AUTOSAR XML (schema 4-3-0)
package /Impl_SWC_HALOUT_ARPkg
  swc implementation Impl_SWC_HALOUT_type: programming-language=C, sw-version=1.0.0, vendor-id=0, behavior=SWC_HALOUT_type_IB
    code-descriptors:
      code SRC: artifact-descriptors=autosar-engineering-object={short-label=EngObject, category=SWSRC}
    resource consumption ResourceConsumption
      memory section MEM_SWC_HALOUT_CAL: size=0, sw-addrmethod=CAL, symbol=CAL
      memory section MEM_SWC_HALOUT_CODE: size=0, sw-addrmethod=CODE, symbol=CODE
package /SWC_HALOUT_ARPkg
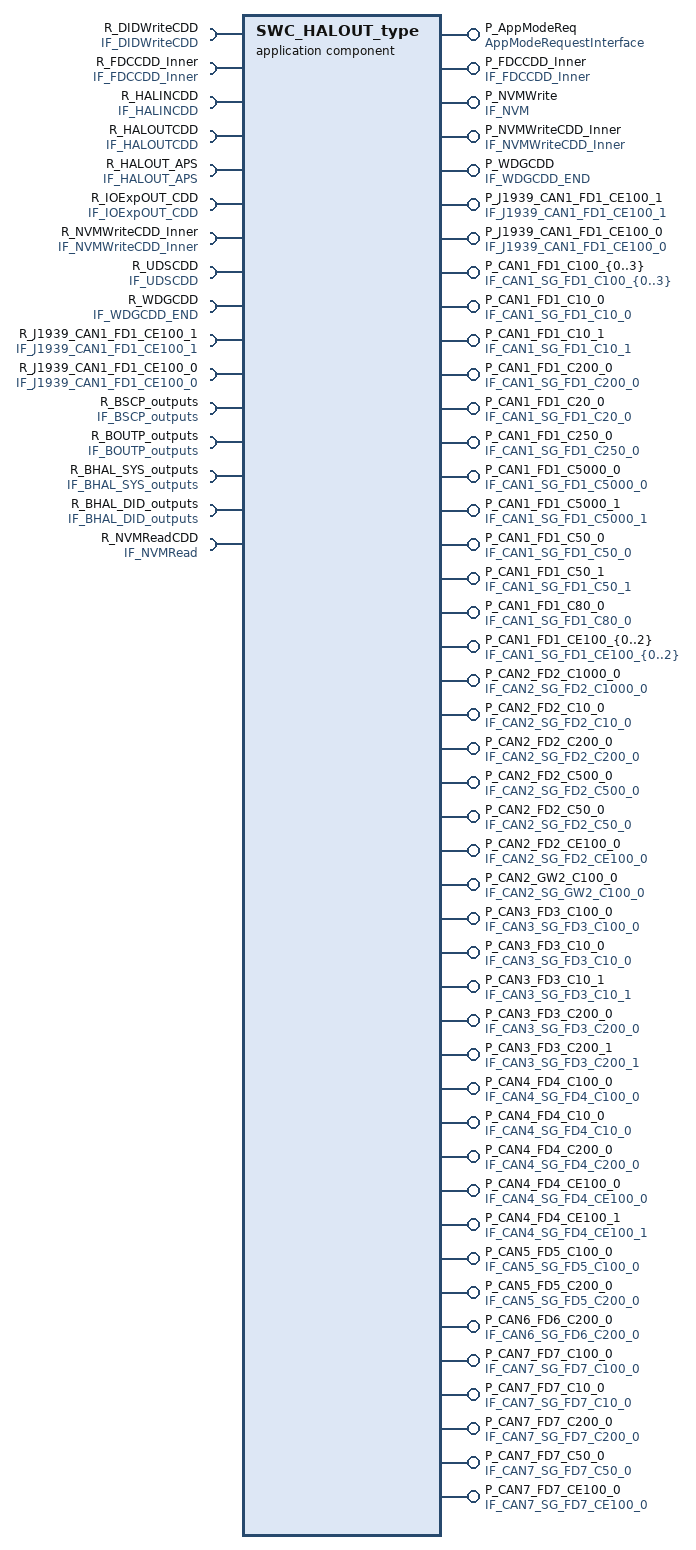
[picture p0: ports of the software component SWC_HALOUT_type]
  application sw component type SWC_HALOUT_type
    49 x provide port:
      P_AppModeReq: provided-interface=AppModeRequestInterface
      P_FDCCDD_Inner: provided-interface=IF_FDCCDD_Inner
      P_NVMWrite: nv-provide-com-spec{ram-block-init-value=ValueSpecification_:1024 x 0, rom-block-init-value=ValueSpecification_:1024 x 0, variable=NV_FVTDataArray}, provided-interface=IF_NVM
      P_NVMWriteCDD_Inner: provided-interface=IF_NVMWriteCDD_Inner
      P_WDGCDD: provided-interface=IF_WDGCDD_END
      P_J1939_CAN1_FD1_CE100_1: provided-interface=IF_J1939_CAN1_FD1_CE100_1
      P_J1939_CAN1_FD1_CE100_0: provided-interface=IF_J1939_CAN1_FD1_CE100_0
      P_CAN1_FD1_C100_{0..3}: provided-interface=IF_CAN1_SG_FD1_C100_{0..3}
      P_CAN1_FD1_C10_0: provided-interface=IF_CAN1_SG_FD1_C10_0
      P_CAN1_FD1_C10_1: provided-interface=IF_CAN1_SG_FD1_C10_1
      P_CAN1_FD1_C200_0: provided-interface=IF_CAN1_SG_FD1_C200_0
      P_CAN1_FD1_C20_0: provided-interface=IF_CAN1_SG_FD1_C20_0
      P_CAN1_FD1_C250_0: provided-interface=IF_CAN1_SG_FD1_C250_0
      P_CAN1_FD1_C5000_0: provided-interface=IF_CAN1_SG_FD1_C5000_0
      P_CAN1_FD1_C5000_1: provided-interface=IF_CAN1_SG_FD1_C5000_1
      P_CAN1_FD1_C50_0: provided-interface=IF_CAN1_SG_FD1_C50_0
      P_CAN1_FD1_C50_1: provided-interface=IF_CAN1_SG_FD1_C50_1
      P_CAN1_FD1_C80_0: provided-interface=IF_CAN1_SG_FD1_C80_0
      P_CAN1_FD1_CE100_{0..2}: provided-interface=IF_CAN1_SG_FD1_CE100_{0..2}
      P_CAN2_FD2_C1000_0: provided-interface=IF_CAN2_SG_FD2_C1000_0
      P_CAN2_FD2_C10_0: provided-interface=IF_CAN2_SG_FD2_C10_0
      P_CAN2_FD2_C200_0: provided-interface=IF_CAN2_SG_FD2_C200_0
      P_CAN2_FD2_C500_0: provided-interface=IF_CAN2_SG_FD2_C500_0
      P_CAN2_FD2_C50_0: provided-interface=IF_CAN2_SG_FD2_C50_0
      P_CAN2_FD2_CE100_0: provided-interface=IF_CAN2_SG_FD2_CE100_0
      P_CAN2_GW2_C100_0: provided-interface=IF_CAN2_SG_GW2_C100_0
      P_CAN3_FD3_C100_0: provided-interface=IF_CAN3_SG_FD3_C100_0
      P_CAN3_FD3_C10_0: provided-interface=IF_CAN3_SG_FD3_C10_0
      P_CAN3_FD3_C10_1: provided-interface=IF_CAN3_SG_FD3_C10_1
      P_CAN3_FD3_C200_0: provided-interface=IF_CAN3_SG_FD3_C200_0
      P_CAN3_FD3_C200_1: provided-interface=IF_CAN3_SG_FD3_C200_1
      P_CAN4_FD4_C100_0: provided-interface=IF_CAN4_SG_FD4_C100_0
      P_CAN4_FD4_C10_0: provided-interface=IF_CAN4_SG_FD4_C10_0
      P_CAN4_FD4_C200_0: provided-interface=IF_CAN4_SG_FD4_C200_0
      P_CAN4_FD4_CE100_0: provided-interface=IF_CAN4_SG_FD4_CE100_0
      P_CAN4_FD4_CE100_1: provided-interface=IF_CAN4_SG_FD4_CE100_1
      P_CAN5_FD5_C100_0: provided-interface=IF_CAN5_SG_FD5_C100_0
      P_CAN5_FD5_C200_0: provided-interface=IF_CAN5_SG_FD5_C200_0
      P_CAN6_FD6_C200_0: provided-interface=IF_CAN6_SG_FD6_C200_0
      P_CAN7_FD7_C100_0: provided-interface=IF_CAN7_SG_FD7_C100_0
      P_CAN7_FD7_C10_0: provided-interface=IF_CAN7_SG_FD7_C10_0
      P_CAN7_FD7_C200_0: provided-interface=IF_CAN7_SG_FD7_C200_0
      P_CAN7_FD7_C50_0: provided-interface=IF_CAN7_SG_FD7_C50_0
      P_CAN7_FD7_CE100_0: provided-interface=IF_CAN7_SG_FD7_CE100_0
    16 x require port:
      R_DIDWriteCDD: required-interface=IF_DIDWriteCDD
      R_FDCCDD_Inner: required-interface=IF_FDCCDD_Inner
      R_HALINCDD: required-interface=IF_HALINCDD
      R_HALOUTCDD: required-interface=IF_HALOUTCDD
      R_HALOUT_APS: required-interface=IF_HALOUT_APS
      R_IOExpOUT_CDD: required-interface=IF_IOExpOUT_CDD
      R_NVMWriteCDD_Inner: required-interface=IF_NVMWriteCDD_Inner
      R_UDSCDD: required-interface=IF_UDSCDD
      R_WDGCDD: required-interface=IF_WDGCDD_END
      R_J1939_CAN1_FD1_CE100_1: required-interface=IF_J1939_CAN1_FD1_CE100_1
      R_J1939_CAN1_FD1_CE100_0: required-interface=IF_J1939_CAN1_FD1_CE100_0
      R_BSCP_outputs: required-interface=IF_BSCP_outputs
      R_BOUTP_outputs: required-interface=IF_BOUTP_outputs
      R_BHAL_SYS_outputs: required-interface=IF_BHAL_SYS_outputs
      R_BHAL_DID_outputs: required-interface=IF_BHAL_DID_outputs
      R_NVMReadCDD: required-interface=IF_NVMRead
    behavior SWC_HALOUT_type_IB: data-type-mapping=AppModeTypeMap, handle-termination-and-restart=NO-SUPPORT
      13 x timing event:
        TE_HALOUT_100ms: start-on-event=run_SWC_HALOUT_Tx_100ms, period=0.1
        TE_HALOUT_1000ms: start-on-event=run_SWC_HALOUT_Tx_1000ms, period=1
        TE_HALOUT_20ms: start-on-event=run_SWC_HALOUT_Tx_20ms, period=0.02
        TE_HALOUT_200ms: start-on-event=run_SWC_HALOUT_Tx_200ms, period=0.2
        TE_HALOUT_250ms: start-on-event=run_SWC_HALOUT_Tx_250ms, period=0.25
        TE_HALOUT_50ms: start-on-event=run_SWC_HALOUT_Tx_50ms, period=0.05
        TE_HALOUT_500ms: start-on-event=run_SWC_HALOUT_Tx_500ms, period=0.5
        TE_HALOUT_5000ms: start-on-event=run_SWC_HALOUT_Tx_5000ms, period=5
        TE_HALOUT_80ms: start-on-event=run_SWC_HALOUT_Tx_80ms, period=0.08
        TE_HALOUT_10ms: start-on-event=run_SWC_HALOUT_Tx_10ms, period=0.01
        TE_HALOUT_5ms: start-on-event=run_SWC_HALOUT_Tx_5ms, period=0.005
        TE_PAS_1ms: start-on-event=run_SWC_HALOUT_PAS_1ms, period=0.001
        TE_UDS_10ms: start-on-event=run_SWC_HALOUT_UDS_10ms, period=0.01
      5 x operation invoked event:
        oie_P_WDGCDD_CSOP_Call_WDG_AppEnd: start-on-event=run_SWC_HALOUT_AppCallWDG_End, operation=P_WDGCDD.CSOP_Call_WDG_AppEnd
        oie_P_FDCCDD_Inner_CSOP_FDC_AppCallSleep: start-on-event=run_SWC_HALOUT_AppCallSleep, operation=P_FDCCDD_Inner.CSOP_FDC_AppCallSleep
        oie_P_NVMWriteCDD_Inner_NVM_WriteOperation: start-on-event=run_SWC_HALOUT_NvmWrite, operation=P_NVMWriteCDD_Inner.NVM_WriteOperation
        oie_P_J1939_CAN1_FD1_CE100_1_CSOP_Write_FD1_CE100_1: start-on-event=run_SWC_HALOUT_J1939_Write_CAN1_FD1_CE100_1, operation=P_J1939_CAN1_FD1_CE100_1.CSOP_Write_CAN1_FD1_CE100_1
        oie_P_J1939_CAN1_FD1_CE100_0_CSOP_Write_FD1_CE100_0: start-on-event=run_SWC_HALOUT_J1939_Write_CAN1_FD1_CE100_0, operation=P_J1939_CAN1_FD1_CE100_0.CSOP_Write_CAN1_FD1_CE100_0
      explicit-inter-runnable-variables:
        44 x data:
          IRV_ms10_CAN1_SG_FD1_C10_0: type=DT_CAN1_SG_FD1_C10_0
          IRV_ms10_CAN1_SG_FD1_C10_1: type=DT_CAN1_SG_FD1_C10_1
          IRV_ms10_CAN2_SG_FD2_C10_0: type=DT_CAN2_SG_FD2_C10_0
          IRV_ms10_CAN3_SG_FD3_C10_0: type=DT_CAN3_SG_FD3_C10_0
          IRV_ms10_CAN3_SG_FD3_C10_1: type=DT_CAN3_SG_FD3_C10_1
          IRV_ms10_CAN4_SG_FD4_C10_0: type=DT_CAN4_SG_FD4_C10_0
          IRV_ms10_CAN7_SG_FD7_C10_0: type=DT_CAN7_SG_FD7_C10_0
          IRV_ms100_CAN1_SG_FD1_C100_{0..3}: type=DT_CAN1_SG_FD1_C100_{0..3}
          IRV_ms100_CAN2_SG_GW2_C100_0: type=DT_CAN2_SG_GW2_C100_0
          IRV_ms100_CAN{3..5}_SG_FD{3..5}_C100_0: type=DT_CAN{3..5}_SG_FD{3..5}_C100_0
          IRV_ms100_CAN7_SG_FD7_C100_0: type=DT_CAN7_SG_FD7_C100_0
          IRV_ms1000_CAN2_SG_FD2_C1000_0: type=DT_CAN2_SG_FD2_C1000_0
          IRV_ms20_CAN1_SG_FD1_C20_0: type=DT_CAN1_SG_FD1_C20_0
          IRV_ms200_CAN{1..3}_SG_FD{1..3}_C200_0: type=DT_CAN{1..3}_SG_FD{1..3}_C200_0
          IRV_ms200_CAN3_SG_FD3_C200_1: type=DT_CAN3_SG_FD3_C200_1
          IRV_ms200_CAN{4..7}_SG_FD{4..7}_C200_0: type=DT_CAN{4..7}_SG_FD{4..7}_C200_0
          IRV_ms250_CAN1_SG_FD1_C250_0: type=DT_CAN1_SG_FD1_C250_0
          IRV_ms50_CAN1_SG_FD1_C50_0: type=DT_CAN1_SG_FD1_C50_0
          IRV_ms50_CAN1_SG_FD1_C50_1: type=DT_CAN1_SG_FD1_C50_1
          IRV_ms50_CAN2_SG_FD2_C50_0: type=DT_CAN2_SG_FD2_C50_0
          IRV_ms50_CAN7_SG_FD7_C50_0: type=DT_CAN7_SG_FD7_C50_0
          IRV_ms500_CAN2_SG_FD2_C500_0: type=DT_CAN2_SG_FD2_C500_0
          IRV_ms5000_CAN1_SG_FD1_C5000_0: type=DT_CAN1_SG_FD1_C5000_0
          IRV_ms5000_CAN1_SG_FD1_C5000_1: type=DT_CAN1_SG_FD1_C5000_1
          IRV_ms80_CAN1_SG_FD1_C80_0: type=DT_CAN1_SG_FD1_C80_0
          IRV_f32_ApsOutVehSpdSig: type=float32
          IRV_u8Array1024_NvmWriteArray: type=u8_FVTNVMArray1024_type
          IRV_u8_ApsOutGearPosnSig: type=uint8
          IRV_u8_ApsOutSendChrgPlugSta: type=uint8
          IRV_u8_ApsOutSetFrSensorOnCmd: type=uint8
          IRV_u8_ApsOutSetFrSensorSwTOCmd: type=uint8
          IRV_u8_ApsOutSetVehSpdTOCmd: type=uint8
          IRV_J1939_CAN1_SG_FD1_CE100_1: type=DT_CAN1_SG_FD1_CE100_1
          IRV_J1939_CAN1_SG_FD1_CE100_0: type=DT_CAN1_SG_FD1_CE100_0
      port-api-options:
        enable-take-address=false, indirect-api=false, port=P_FDCCDD_Inner
        enable-take-address=false, indirect-api=false, port=P_NVMWriteCDD_Inner
        enable-take-address=false, indirect-api=false, port=P_WDGCDD
        enable-take-address=false, indirect-api=false, port=P_J1939_CAN1_FD1_CE100_1
        enable-take-address=false, indirect-api=false, port=P_J1939_CAN1_FD1_CE100_0
      18 x runnable:
        run_SWC_HALOUT_Tx_100ms
          data-send-points:
            9 x access:
              dsp_CAN1_SG_FD1_C100_{0..3}: accessed-variable=P_CAN1_FD1_C100_{0..3}.CAN1_SG_FD1_C100_{0..3}
              dsp_CAN2_SG_GW2_C100_0: accessed-variable=P_CAN2_GW2_C100_0.CAN2_SG_GW2_C100_0
              dsp_CAN{3..5}_SG_FD{3..5}_C100_0: accessed-variable=P_CAN{3..5}_FD{3..5}_C100_0.CAN{3..5}_SG_FD{3..5}_C100_0
              dsp_CAN7_SG_FD7_C100_0: accessed-variable=P_CAN7_FD7_C100_0.CAN7_SG_FD7_C100_0
          read-local-variables:
            9 x access:
              IRV_ms100_CAN1_SG_FD1_C100_{0..3}: accessed-variable=IRV_ms100_CAN1_SG_FD1_C100_{0..3}
              IRV_ms100_CAN2_SG_GW2_C100_0: accessed-variable=IRV_ms100_CAN2_SG_GW2_C100_0
              IRV_ms100_CAN{3..5}_SG_FD{3..5}_C100_0: accessed-variable=IRV_ms100_CAN{3..5}_SG_FD{3..5}_C100_0
              IRV_ms100_CAN7_SG_FD7_C100_0: accessed-variable=IRV_ms100_CAN7_SG_FD7_C100_0
        run_SWC_HALOUT_Tx_1000ms
          data-send-points:
            access dsp_CAN2_SG_FD2_C1000_0: accessed-variable=P_CAN2_FD2_C1000_0.CAN2_SG_FD2_C1000_0
          read-local-variables:
            access IRV_ms1000_CAN2_SG_FD2_C1000_0: accessed-variable=IRV_ms1000_CAN2_SG_FD2_C1000_0
        run_SWC_HALOUT_Tx_20ms
          data-send-points:
            access dsp_CAN1_SG_FD1_C20_0: accessed-variable=P_CAN1_FD1_C20_0.CAN1_SG_FD1_C20_0
          read-local-variables:
            access IRV_ms20_CAN1_SG_FD1_C20_0: accessed-variable=IRV_ms20_CAN1_SG_FD1_C20_0
        run_SWC_HALOUT_Tx_200ms
          data-send-points:
            8 x access:
              dsp_CAN{1..3}_SG_FD{1..3}_C200_0: accessed-variable=P_CAN{1..3}_FD{1..3}_C200_0.CAN{1..3}_SG_FD{1..3}_C200_0
              dsp_CAN3_SG_FD3_C200_1: accessed-variable=P_CAN3_FD3_C200_1.CAN3_SG_FD3_C200_1
              dsp_CAN{4..7}_SG_FD{4..7}_C200_0: accessed-variable=P_CAN{4..7}_FD{4..7}_C200_0.CAN{4..7}_SG_FD{4..7}_C200_0
          read-local-variables:
            8 x access:
              IRV_ms200_CAN{1..3}_SG_FD{1..3}_C200_0: accessed-variable=IRV_ms200_CAN{1..3}_SG_FD{1..3}_C200_0
              IRV_ms200_CAN3_SG_FD3_C200_1: accessed-variable=IRV_ms200_CAN3_SG_FD3_C200_1
              IRV_ms200_CAN{4..7}_SG_FD{4..7}_C200_0: accessed-variable=IRV_ms200_CAN{4..7}_SG_FD{4..7}_C200_0
        run_SWC_HALOUT_Tx_250ms
          data-send-points:
            access dsp_CAN1_SG_FD1_C250_0: accessed-variable=P_CAN1_FD1_C250_0.CAN1_SG_FD1_C250_0
          read-local-variables:
            access IRV_ms250_CAN1_SG_FD1_C250_0: accessed-variable=IRV_ms250_CAN1_SG_FD1_C250_0
        run_SWC_HALOUT_Tx_50ms
          data-send-points:
            4 x access:
              dsp_CAN1_SG_FD1_C50_0: accessed-variable=P_CAN1_FD1_C50_0.CAN1_SG_FD1_C50_0
              dsp_CAN1_SG_FD1_C50_1: accessed-variable=P_CAN1_FD1_C50_1.CAN1_SG_FD1_C50_1
              dsp_CAN2_SG_FD2_C50_0: accessed-variable=P_CAN2_FD2_C50_0.CAN2_SG_FD2_C50_0
              dsp_CAN7_SG_FD7_C50_0: accessed-variable=P_CAN7_FD7_C50_0.CAN7_SG_FD7_C50_0
          read-local-variables:
            4 x access:
              IRV_ms50_CAN1_SG_FD1_C50_0: accessed-variable=IRV_ms50_CAN1_SG_FD1_C50_0
              IRV_ms50_CAN1_SG_FD1_C50_1: accessed-variable=IRV_ms50_CAN1_SG_FD1_C50_1
              IRV_ms50_CAN2_SG_FD2_C50_0: accessed-variable=IRV_ms50_CAN2_SG_FD2_C50_0
              IRV_ms50_CAN7_SG_FD7_C50_0: accessed-variable=IRV_ms50_CAN7_SG_FD7_C50_0
        run_SWC_HALOUT_Tx_500ms
          data-send-points:
            access dsp_CAN2_SG_FD2_C500_0: accessed-variable=P_CAN2_FD2_C500_0.CAN2_SG_FD2_C500_0
          read-local-variables:
            access IRV_ms500_CAN2_SG_FD2_C500_0: accessed-variable=IRV_ms500_CAN2_SG_FD2_C500_0
        run_SWC_HALOUT_Tx_5000ms
          data-send-points:
            access dsp_CAN1_SG_FD1_C5000_0: accessed-variable=P_CAN1_FD1_C5000_0.CAN1_SG_FD1_C5000_0
            access dsp_CAN1_SG_FD1_C5000_1: accessed-variable=P_CAN1_FD1_C5000_1.CAN1_SG_FD1_C5000_1
          read-local-variables:
            access IRV_ms5000_CAN1_SG_FD1_C5000_0: accessed-variable=IRV_ms5000_CAN1_SG_FD1_C5000_0
            access IRV_ms5000_CAN1_SG_FD1_C5000_1: accessed-variable=IRV_ms5000_CAN1_SG_FD1_C5000_1
        run_SWC_HALOUT_Tx_80ms
          data-send-points:
            access dsp_CAN1_SG_FD1_C80_0: accessed-variable=P_CAN1_FD1_C80_0.CAN1_SG_FD1_C80_0
          read-local-variables:
            access IRV_ms80_CAN1_SG_FD1_C80_0: accessed-variable=IRV_ms80_CAN1_SG_FD1_C80_0
        run_SWC_HALOUT_AppCallSleep
          data-send-points:
            access dsp_requestedMode: accessed-variable=P_AppModeReq.requestedMode
        run_SWC_HALOUT_NvmWrite
          data-send-points:
            access dsp_NV_FVTDataArray: accessed-variable=P_NVMWrite.NV_FVTDataArray
          read-local-variables:
            access IRV_u8Array1024_NvmWriteArray: accessed-variable=IRV_u8Array1024_NvmWriteArray
        run_SWC_HALOUT_PAS_1ms
          sync call scp_CSOP_PAS_Handler: operation=R_HALINCDD.CSOP_PAS_Handler, timeout=0.0
        run_SWC_HALOUT_Tx_5ms
          data-receive-point-by-arguments:
            5 x access:
              drparg_BSCP_outputs: accessed-variable=R_BSCP_outputs.BSCP_outputs
              drparg_BOUTP_outputs: accessed-variable=R_BOUTP_outputs.BOUTP_outputs
              drparg_BHAL_SYS_outputs: accessed-variable=R_BHAL_SYS_outputs.BHAL_SYS_outputs
              drparg_BHAL_DID_outputs: accessed-variable=R_BHAL_DID_outputs.BHAL_DID_outputs
              drparg_u8_FVTNVMArray1024_type: accessed-variable=R_NVMReadCDD.u8Array1024_NVMReadData
          data-send-points:
            5 x access:
              dsp_CAN1_SG_FD1_CE100_2: accessed-variable=P_CAN1_FD1_CE100_2.CAN1_SG_FD1_CE100_2
              dsp_CAN2_SG_FD2_CE100_0: accessed-variable=P_CAN2_FD2_CE100_0.CAN2_SG_FD2_CE100_0
              dsp_CAN4_SG_FD4_CE100_0: accessed-variable=P_CAN4_FD4_CE100_0.CAN4_SG_FD4_CE100_0
              dsp_CAN4_SG_FD4_CE100_1: accessed-variable=P_CAN4_FD4_CE100_1.CAN4_SG_FD4_CE100_1
              dsp_CAN7_SG_FD7_CE100_0: accessed-variable=P_CAN7_FD7_CE100_0.CAN7_SG_FD7_CE100_0
          48 x sync call, all with timeout=0.0:
            scp_CSOP_ApsSetData: operation=R_HALOUT_APS.CSOP_ApsSetData
            scp_CSOP_ApsSetTimeout: operation=R_HALOUT_APS.CSOP_ApsSetTimeout
            scp_CSOP_DdmRestartOperation: operation=R_UDSCDD.CSOP_DdmRestartOperationCycle
            scp_CSOP_FDC_AppCallSleep: operation=R_FDCCDD_Inner.CSOP_FDC_AppCallSleep
            scp_CSOP_IOExpSetVal: operation=R_IOExpOUT_CDD.CSOP_IOExpSetVal
            scp_CSOP_SetAcoreRebootCmdACK: operation=R_HALOUTCDD.CSOP_SetAcoreRebootCmdACK
            scp_CSOP_SetDTCStatus: operation=R_UDSCDD.CSOP_SetDTCStatus
            scp_CSOP_SetHazardIND: operation=R_HALOUTCDD.CSOP_SetHazardIND
            scp_CSOP_SetSysPwrStat: operation=R_HALOUTCDD.CSOP_SetSysPwrStat
            scp_CSOP_AppNmStateReq: operation=R_HALOUTCDD.CSOP_AppNmStateReq
            scp_CSOP_Call_WDG_AppEnd: operation=R_WDGCDD.CSOP_Call_WDG_AppEnd
            scp_CSOP_SleepRequest: operation=R_HALOUTCDD.CSOP_SleepRequest
            scp_CSOP_TPMSSensorIDRegSetResults: operation=R_HALOUTCDD.CSOP_TPMSSensorIDRegSetResults
            scp_CSOP_ResetPedalZeroPosDone: operation=R_HALOUTCDD.CSOP_ResetPedalZeroPosDone
            scp_NVM_WriteOperation: operation=R_NVMWriteCDD_Inner.NVM_WriteOperation
            scp_CSOP_Write_CAN1_FD1_CE100_0: operation=R_J1939_CAN1_FD1_CE100_0.CSOP_Write_CAN1_FD1_CE100_0
            scp_CSOP_DIDSet_XWDMode: operation=R_DIDWriteCDD.CSOP_DIDSet_XWDMode
            scp_CSOP_DIDSet_DKCKey: operation=R_DIDWriteCDD.CSOP_DIDSet_DKCKey
            scp_CSOP_DIDSet_DynoMode: operation=R_DIDWriteCDD.CSOP_DIDSet_DynoMode
            scp_CSOP_DIDSet_APPPedalZP: operation=R_DIDWriteCDD.CSOP_DIDSet_APPPedalZP
            scp_CSOP_DIDSet_NVMPedalZP: operation=R_DIDWriteCDD.CSOP_DIDSet_NVMPedalZP
            scp_CSOP_DIDSet_TurnLampFRThreCurr: operation=R_DIDWriteCDD.CSOP_DIDSet_TurnLampFRThreCurr
            scp_CSOP_DIDSet_TurnLampRRThreCurr: operation=R_DIDWriteCDD.CSOP_DIDSet_TurnLampRRThreCurr
            scp_CSOP_DIDSet_TurnLampFLThreCurr: operation=R_DIDWriteCDD.CSOP_DIDSet_TurnLampFLThreCurr
            scp_CSOP_DIDSet_TurnLampRLThreCurr: operation=R_DIDWriteCDD.CSOP_DIDSet_TurnLampRLThreCurr
            scp_CSOP_DIDSet_FMHTimer: operation=R_DIDWriteCDD.CSOP_DIDSet_FMHTimer
            scp_CSOP_DIDSet_AutoLock: operation=R_DIDWriteCDD.CSOP_DIDSet_AutoLock
            scp_CSOP_DIDSet_DRLDis: operation=R_DIDWriteCDD.CSOP_DIDSet_DRLDis
            scp_CSOP_DIDSet_AutoWipHSpdEN: operation=R_DIDWriteCDD.CSOP_DIDSet_AutoWipHSpdEN
            scp_CSOP_DIDSet_WipRLSCmdHoldFilter: operation=R_DIDWriteCDD.CSOP_DIDSet_WipRLSCmdHoldFilter
            scp_CSOP_DIDSet_WipRLSCmdCutFilter: operation=R_DIDWriteCDD.CSOP_DIDSet_WipRLSCmdCutFilter
            scp_CSOP_DIDSet_LFSensorID: operation=R_DIDWriteCDD.CSOP_DIDSet_LFSensorID
            scp_CSOP_DIDSet_RFSensorID: operation=R_DIDWriteCDD.CSOP_DIDSet_RFSensorID
            scp_CSOP_DIDSet_LRSensorID: operation=R_DIDWriteCDD.CSOP_DIDSet_LRSensorID
            scp_CSOP_DIDSet_RRSensorID: operation=R_DIDWriteCDD.CSOP_DIDSet_RRSensorID
            scp_CSOP_DIDSet_WhlPres: operation=R_DIDWriteCDD.CSOP_DIDSet_WhlPres
            scp_CSOP_DIDSet_WhlTmp: operation=R_DIDWriteCDD.CSOP_DIDSet_WhlTmp
            scp_CSOP_DIDSet_WhlSensorBattSta: operation=R_DIDWriteCDD.CSOP_DIDSet_WhlSensorBattSta
            scp_CSOP_DIDSet_LFLowPresThre: operation=R_DIDWriteCDD.CSOP_DIDSet_LFLowPresThre
            scp_CSOP_DIDSet_RFLowPresThre: operation=R_DIDWriteCDD.CSOP_DIDSet_RFLowPresThre
            scp_CSOP_DIDSet_LRLowPresThre: operation=R_DIDWriteCDD.CSOP_DIDSet_LRLowPresThre
            scp_CSOP_DIDSet_RRLowPresThre: operation=R_DIDWriteCDD.CSOP_DIDSet_RRLowPresThre
            scp_CSOP_DIDSet_SensorMode: operation=R_DIDWriteCDD.CSOP_DIDSet_SensorMode
            scp_CSOP_DIDSet_TPMSLearnSta: operation=R_DIDWriteCDD.CSOP_DIDSet_TPMSLearnSta
            scp_CSOP_DIDSet_USSConfig: operation=R_DIDWriteCDD.CSOP_DIDSet_USSConfig
            scp_CSOP_DIDSet_TireSize: operation=R_DIDWriteCDD.CSOP_DIDSet_TireSize
            scp_CSOP_DIDSet_APSFunConfig: operation=R_DIDWriteCDD.CSOP_DIDSet_APSFunConfig
            scp_CSOP_Write_CAN1_FD1_CE100_1: operation=R_J1939_CAN1_FD1_CE100_1.CSOP_Write_CAN1_FD1_CE100_1
          written-local-variables:
            44 x access:
              IRV_ms10_CAN1_SG_FD1_C10_0: accessed-variable=IRV_ms10_CAN1_SG_FD1_C10_0
              IRV_ms10_CAN1_SG_FD1_C10_1: accessed-variable=IRV_ms10_CAN1_SG_FD1_C10_1
              IRV_ms10_CAN2_SG_FD2_C10_0: accessed-variable=IRV_ms10_CAN2_SG_FD2_C10_0
              IRV_ms10_CAN3_SG_FD3_C10_0: accessed-variable=IRV_ms10_CAN3_SG_FD3_C10_0
              IRV_ms10_CAN3_SG_FD3_C10_1: accessed-variable=IRV_ms10_CAN3_SG_FD3_C10_1
              IRV_ms10_CAN4_SG_FD4_C10_0: accessed-variable=IRV_ms10_CAN4_SG_FD4_C10_0
              IRV_ms10_CAN7_SG_FD7_C10_0: accessed-variable=IRV_ms10_CAN7_SG_FD7_C10_0
              IRV_ms100_CAN1_SG_FD1_C100_{0..3}: accessed-variable=IRV_ms100_CAN1_SG_FD1_C100_{0..3}
              IRV_ms100_CAN2_SG_GW2_C100_0: accessed-variable=IRV_ms100_CAN2_SG_GW2_C100_0
              IRV_ms100_CAN{3..5}_SG_FD{3..5}_C100_0: accessed-variable=IRV_ms100_CAN{3..5}_SG_FD{3..5}_C100_0
              IRV_ms100_CAN7_SG_FD7_C100_0: accessed-variable=IRV_ms100_CAN7_SG_FD7_C100_0
              IRV_ms1000_CAN2_SG_FD2_C1000_0: accessed-variable=IRV_ms1000_CAN2_SG_FD2_C1000_0
              IRV_ms20_CAN1_SG_FD1_C20_0: accessed-variable=IRV_ms20_CAN1_SG_FD1_C20_0
              IRV_ms200_CAN{1..3}_SG_FD{1..3}_C200_0: accessed-variable=IRV_ms200_CAN{1..3}_SG_FD{1..3}_C200_0
              IRV_ms200_CAN3_SG_FD3_C200_1: accessed-variable=IRV_ms200_CAN3_SG_FD3_C200_1
              IRV_ms200_CAN{4..7}_SG_FD{4..7}_C200_0: accessed-variable=IRV_ms200_CAN{4..7}_SG_FD{4..7}_C200_0
              IRV_ms250_CAN1_SG_FD1_C250_0: accessed-variable=IRV_ms250_CAN1_SG_FD1_C250_0
              IRV_ms50_CAN1_SG_FD1_C50_0: accessed-variable=IRV_ms50_CAN1_SG_FD1_C50_0
              IRV_ms50_CAN1_SG_FD1_C50_1: accessed-variable=IRV_ms50_CAN1_SG_FD1_C50_1
              IRV_ms50_CAN2_SG_FD2_C50_0: accessed-variable=IRV_ms50_CAN2_SG_FD2_C50_0
              IRV_ms50_CAN7_SG_FD7_C50_0: accessed-variable=IRV_ms50_CAN7_SG_FD7_C50_0
              IRV_ms500_CAN2_SG_FD2_C500_0: accessed-variable=IRV_ms500_CAN2_SG_FD2_C500_0
              IRV_ms5000_CAN1_SG_FD1_C5000_0: accessed-variable=IRV_ms5000_CAN1_SG_FD1_C5000_0
              IRV_ms5000_CAN1_SG_FD1_C5000_1: accessed-variable=IRV_ms5000_CAN1_SG_FD1_C5000_1
              IRV_ms80_CAN1_SG_FD1_C80_0: accessed-variable=IRV_ms80_CAN1_SG_FD1_C80_0
              IRV_f32_ApsOutVehSpdSig: accessed-variable=IRV_f32_ApsOutVehSpdSig
              IRV_u8Array1024_NvmWriteArray: accessed-variable=IRV_u8Array1024_NvmWriteArray
              IRV_u8_ApsOutGearPosnSig: accessed-variable=IRV_u8_ApsOutGearPosnSig
              IRV_u8_ApsOutSendChrgPlugSta: accessed-variable=IRV_u8_ApsOutSendChrgPlugSta
              IRV_u8_ApsOutSetFrSensorOnCmd: accessed-variable=IRV_u8_ApsOutSetFrSensorOnCmd
              IRV_u8_ApsOutSetFrSensorSwTOCmd: accessed-variable=IRV_u8_ApsOutSetFrSensorSwTOCmd
              IRV_u8_ApsOutSetVehSpdTOCmd: accessed-variable=IRV_u8_ApsOutSetVehSpdTOCmd
              IRV_J1939_CAN1_SG_FD1_CE100_0: accessed-variable=IRV_J1939_CAN1_SG_FD1_CE100_0
              IRV_J1939_CAN1_SG_FD1_CE100_1: accessed-variable=IRV_J1939_CAN1_SG_FD1_CE100_1
        run_SWC_HALOUT_Tx_10ms
          data-send-points:
            7 x access:
              dsp_CAN1_SG_FD1_C10_0: accessed-variable=P_CAN1_FD1_C10_0.CAN1_SG_FD1_C10_0
              dsp_CAN1_SG_FD1_C10_1: accessed-variable=P_CAN1_FD1_C10_1.CAN1_SG_FD1_C10_1
              dsp_CAN2_SG_FD2_C10_0: accessed-variable=P_CAN2_FD2_C10_0.CAN2_SG_FD2_C10_0
              dsp_CAN3_SG_FD3_C10_0: accessed-variable=P_CAN3_FD3_C10_0.CAN3_SG_FD3_C10_0
              dsp_CAN3_SG_FD3_C10_1: accessed-variable=P_CAN3_FD3_C10_1.CAN3_SG_FD3_C10_1
              dsp_CAN4_SG_FD4_C10_0: accessed-variable=P_CAN4_FD4_C10_0.CAN4_SG_FD4_C10_0
              dsp_CAN7_SG_FD7_C10_0: accessed-variable=P_CAN7_FD7_C10_0.CAN7_SG_FD7_C10_0
          read-local-variables:
            13 x access:
              IRV_ms10_CAN1_SG_FD1_C10_0: accessed-variable=IRV_ms10_CAN1_SG_FD1_C10_0
              IRV_ms10_CAN1_SG_FD1_C10_1: accessed-variable=IRV_ms10_CAN1_SG_FD1_C10_1
              IRV_ms10_CAN2_SG_FD2_C10_0: accessed-variable=IRV_ms10_CAN2_SG_FD2_C10_0
              IRV_ms10_CAN3_SG_FD3_C10_0: accessed-variable=IRV_ms10_CAN3_SG_FD3_C10_0
              IRV_ms10_CAN3_SG_FD3_C10_1: accessed-variable=IRV_ms10_CAN3_SG_FD3_C10_1
              IRV_ms10_CAN4_SG_FD4_C10_0: accessed-variable=IRV_ms10_CAN4_SG_FD4_C10_0
              IRV_ms10_CAN7_SG_FD7_C10_0: accessed-variable=IRV_ms10_CAN7_SG_FD7_C10_0
              IRV_f32_ApsOutVehSpdSig: accessed-variable=IRV_f32_ApsOutVehSpdSig
              IRV_u8_ApsOutGearPosnSig: accessed-variable=IRV_u8_ApsOutGearPosnSig
              IRV_u8_ApsOutSendChrgPlugSta: accessed-variable=IRV_u8_ApsOutSendChrgPlugSta
              IRV_u8_ApsOutSetFrSensorOnCmd: accessed-variable=IRV_u8_ApsOutSetFrSensorOnCmd
              IRV_u8_ApsOutSetFrSensorSwTOCmd: accessed-variable=IRV_u8_ApsOutSetFrSensorSwTOCmd
              IRV_u8_ApsOutSetVehSpdTOCmd: accessed-variable=IRV_u8_ApsOutSetVehSpdTOCmd
          sync call scp_CSOP_ApsOutput: operation=R_HALOUT_APS.CSOP_ApsOutput, timeout=0.0
        run_SWC_HALOUT_UDS_10ms
          sync call scp_CSOP_UDS_Main: operation=R_HALINCDD.CSOP_UDS_Main, timeout=0.0
        run_SWC_HALOUT_AppCallWDG_End
        run_SWC_HALOUT_J1939_Write_CAN1_FD1_CE100_1
          data-send-points:
            access dsp_CAN1_SG_FD1_CE100_1: accessed-variable=P_CAN1_FD1_CE100_1.CAN1_SG_FD1_CE100_1
          read-local-variables:
            access IRV_J1939_CAN1_SG_FD1_CE100_1: accessed-variable=IRV_J1939_CAN1_SG_FD1_CE100_1
        run_SWC_HALOUT_J1939_Write_CAN1_FD1_CE100_0
          data-send-points:
            access dsp_CAN1_SG_FD1_CE100_0: accessed-variable=P_CAN1_FD1_CE100_0.CAN1_SG_FD1_CE100_0
          read-local-variables:
            access IRV_J1939_CAN1_SG_FD1_CE100_0: accessed-variable=IRV_J1939_CAN1_SG_FD1_CE100_0
